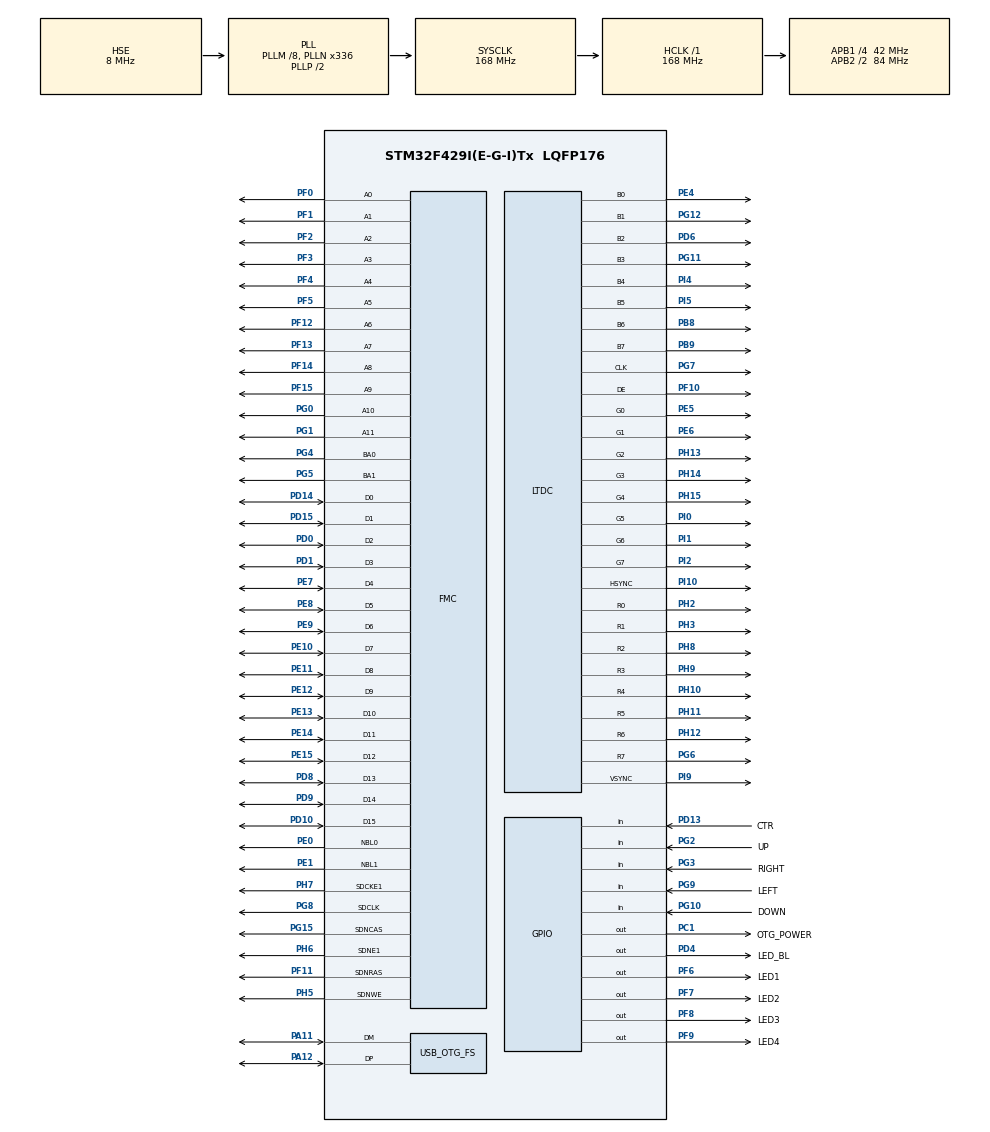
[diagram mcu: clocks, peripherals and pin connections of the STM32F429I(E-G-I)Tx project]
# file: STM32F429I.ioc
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DMA2D.ColorMode=DMA2D_RGB565
DMA2D.InputAlphaForeground=0xFF
DMA2D.InputColorModeForeground=CM_RGB565
DMA2D.Mode=DMA2D_M2M
Dma.MEMTOMEM.0.Channel=DMA_CHANNEL_0
Dma.MEMTOMEM.0.Direction=DMA_MEMORY_TO_MEMORY
Dma.MEMTOMEM.0.FIFOMode=DMA_FIFOMODE_ENABLE
Dma.MEMTOMEM.0.FIFOThreshold=DMA_FIFO_THRESHOLD_FULL
Dma.MEMTOMEM.0.Instance=DMA2_Stream0
Dma.MEMTOMEM.0.MemBurst=DMA_MBURST_SINGLE
Dma.MEMTOMEM.0.MemDataAlignment=DMA_MDATAALIGN_WORD
Dma.MEMTOMEM.0.MemInc=DMA_MINC_ENABLE
Dma.MEMTOMEM.0.Mode=DMA_NORMAL
Dma.MEMTOMEM.0.PeriphBurst=DMA_PBURST_SINGLE
Dma.MEMTOMEM.0.PeriphDataAlignment=DMA_PDATAALIGN_WORD
Dma.MEMTOMEM.0.PeriphInc=DMA_PINC_ENABLE
Dma.MEMTOMEM.0.Priority=DMA_PRIORITY_LOW
Dma.Request0=MEMTOMEM
FMC.CASLatency1=FMC_SDRAM_CAS_LATENCY_3
FMC.ExitSelfRefreshDelay1=7
FMC.LoadToActiveDelay1=2
FMC.RCDDelay1=2
FMC.RPDelay1=2
FMC.RPDelay2=2
FMC.ReadPipeDelay1=FMC_SDRAM_RPIPE_DELAY_1
FMC.ReadPipeDelay2=FMC_SDRAM_RPIPE_DELAY_1
FMC.RowBitsNumber1=FMC_SDRAM_ROW_BITS_NUM_12
FMC.RowCycleDelay1=6
FMC.RowCycleDelay2=6
FMC.SDClockPeriod1=FMC_SDRAM_CLOCK_PERIOD_2
FMC.SDClockPeriod2=FMC_SDRAM_CLOCK_PERIOD_2
FMC.SelfRefreshTime1=4
FMC.WriteRecoveryTime1=2
LTDC.ActiveH=480
LTDC.ActiveW=800
LTDC.Alpha_L0=255
LTDC.BlendingFactor1_L0=LTDC_BLENDING_FACTOR1_CA
LTDC.BlendingFactor1_L1=LTDC_BLENDING_FACTOR1_PAxCA
LTDC.BlendingFactor2_L0=LTDC_BLENDING_FACTOR2_CA
LTDC.BlendingFactor2_L1=LTDC_BLENDING_FACTOR2_PAxCA
LTDC.FBStartAdress_L0=0xD0000000
LTDC.FBStartAdress_L1=0xD0200000
LTDC.HBP=46
LTDC.HFP=210
LTDC.HSync=30
LTDC.ImageHeight_L0=480
LTDC.ImageHeight_L1=480
LTDC.ImageWidth_L0=800
LTDC.ImageWidth_L1=800
LTDC.PixelFormat_L0=LTDC_PIXEL_FORMAT_RGB565
LTDC.PixelFormat_L1=LTDC_PIXEL_FORMAT_RGB565
LTDC.VBP=23
LTDC.VFP=22
LTDC.VSync=10
LTDC.WindowX0_L0=0
LTDC.WindowX0_L1=0
LTDC.WindowX1_L0=800
LTDC.WindowX1_L1=800
LTDC.WindowY0_L0=0
LTDC.WindowY0_L1=0
LTDC.WindowY1_L0=480
LTDC.WindowY1_L1=480
Mcu.Family=STM32F4
Mcu.Name=STM32F429I(E-G-I)Tx
Mcu.Package=LQFP176
NVIC.OTG_FS_IRQn=true\:1\:0\:true
NVIC.PriorityGroup=NVIC_PRIORITYGROUP_4
PA11.Mode=Host_Only
PA11.Signal=USB_OTG_FS_DM
PA12.GPIO_PuPd=GPIO_PULLUP
PA12.Mode=Host_Only
PA12.Signal=USB_OTG_FS_DP
PB8.GPIO_Speed=GPIO_SPEED_HIGH
PB8.Mode=RGB888
PB8.Signal=LTDC_B6
PB9.GPIO_Speed=GPIO_SPEED_HIGH
PB9.Mode=RGB888
PB9.Signal=LTDC_B7
PC1.GPIO_Label=OTG_POWER
PC1.Signal=GPIO_Output
PD0.Signal=FMC_D2_DA2
PD1.Signal=FMC_D3_DA3
PD10.Signal=FMC_D15_DA15
PD13.GPIO_Label=CTR
PD13.GPIO_PuPd=GPIO_PULLUP
PD13.Signal=GPIO_Input
PD14.Signal=FMC_D0_DA0
PD15.Signal=FMC_D1_DA1
PD4.GPIO_Label=LED_BL
PD4.Signal=GPIO_Output
PD6.GPIO_Speed=GPIO_SPEED_HIGH
PD6.Mode=RGB888
PD6.Signal=LTDC_B2
PD8.Signal=FMC_D13_DA13
PD9.Signal=FMC_D14_DA14
PE0.Signal=FMC_NBL0
PE1.Signal=FMC_NBL1
PE10.Signal=FMC_D7_DA7
PE11.Signal=FMC_D8_DA8
PE12.Signal=FMC_D9_DA9
PE13.Signal=FMC_D10_DA10
PE14.Signal=FMC_D11_DA11
PE15.Signal=FMC_D12_DA12
PE4.GPIO_Speed=GPIO_SPEED_HIGH
PE4.Mode=RGB888
PE4.Signal=LTDC_B0
PE5.GPIO_Speed=GPIO_SPEED_HIGH
PE5.Mode=RGB888
PE5.Signal=LTDC_G0
PE6.GPIO_Speed=GPIO_SPEED_HIGH
PE6.Mode=RGB888
PE6.Signal=LTDC_G1
PE7.Signal=FMC_D4_DA4
PE8.Signal=FMC_D5_DA5
PE9.Signal=FMC_D6_DA6
PF0.Signal=FMC_A0
PF1.Signal=FMC_A1
PF10.GPIO_Speed=GPIO_SPEED_HIGH
PF10.Mode=RGB888
PF10.Signal=LTDC_DE
PF11.Signal=FMC_SDNRAS
PF12.Signal=FMC_A6
PF13.Signal=FMC_A7
PF14.Signal=FMC_A8
PF15.Signal=FMC_A9
PF2.Signal=FMC_A2
PF3.Signal=FMC_A3
PF4.Signal=FMC_A4
PF5.Signal=FMC_A5
PF6.GPIO_Label=LED1
PF6.Signal=GPIO_Output
PF7.GPIO_Label=LED2
PF7.Signal=GPIO_Output
PF8.GPIO_Label=LED3
PF8.Signal=GPIO_Output
PF9.GPIO_Label=LED4
PF9.Signal=GPIO_Output
PG0.Signal=FMC_A10
PG1.Signal=FMC_A11
PG10.GPIO_Label=DOWN
PG10.GPIO_PuPd=GPIO_PULLUP
PG10.Signal=GPIO_Input
PG11.GPIO_Speed=GPIO_SPEED_HIGH
PG11.Mode=RGB888
PG11.Signal=LTDC_B3
PG12.GPIO_Speed=GPIO_SPEED_HIGH
PG12.Mode=RGB888
PG12.Signal=LTDC_B1
PG15.Signal=FMC_SDNCAS
PG2.GPIO_Label=UP
PG2.GPIO_PuPd=GPIO_PULLUP
PG2.Signal=GPIO_Input
PG3.GPIO_Label=RIGHT
PG3.GPIO_PuPd=GPIO_PULLUP
PG3.Signal=GPIO_Input
PG4.Signal=FMC_A14_BA0
PG5.Signal=FMC_A15_BA1
PG6.GPIO_Speed=GPIO_SPEED_HIGH
PG6.Mode=RGB888
PG6.Signal=LTDC_R7
PG7.GPIO_Speed=GPIO_SPEED_HIGH
PG7.Mode=RGB888
PG7.Signal=LTDC_CLK
PG8.Signal=FMC_SDCLK
PG9.GPIO_Label=LEFT
PG9.GPIO_PuPd=GPIO_PULLUP
PG9.Signal=GPIO_Input
PH0/OSC_IN.Mode=HSE-External-Oscillator
PH0/OSC_IN.Signal=RCC_OSC_IN
PH1/OSC_OUT.Mode=HSE-External-Oscillator
PH1/OSC_OUT.Signal=RCC_OSC_OUT
PH10.GPIO_Speed=GPIO_SPEED_HIGH
PH10.Mode=RGB888
PH10.Signal=LTDC_R4
PH11.GPIO_Speed=GPIO_SPEED_HIGH
PH11.Mode=RGB888
PH11.Signal=LTDC_R5
PH12.GPIO_Speed=GPIO_SPEED_HIGH
PH12.Mode=RGB888
PH12.Signal=LTDC_R6
PH13.GPIO_Speed=GPIO_SPEED_HIGH
PH13.Mode=RGB888
PH13.Signal=LTDC_G2
PH14.GPIO_Speed=GPIO_SPEED_HIGH
PH14.Mode=RGB888
PH14.Signal=LTDC_G3
PH15.GPIO_Speed=GPIO_SPEED_HIGH
PH15.Mode=RGB888
PH15.Signal=LTDC_G4
PH2.GPIO_Speed=GPIO_SPEED_HIGH
PH2.Mode=RGB888
PH2.Signal=LTDC_R0
PH3.GPIO_Speed=GPIO_SPEED_HIGH
PH3.Mode=RGB888
PH3.Signal=LTDC_R1
PH5.Signal=FMC_SDNWE
PH6.Mode=SdramChipSelect2_1
PH6.Signal=FMC_SDNE1
PH7.Mode=SdramChipSelect2_1
PH7.Signal=FMC_SDCKE1
PH8.GPIO_Speed=GPIO_SPEED_HIGH
PH8.Mode=RGB888
PH8.Signal=LTDC_R2
PH9.GPIO_Speed=GPIO_SPEED_HIGH
PH9.Mode=RGB888
PH9.Signal=LTDC_R3
PI0.GPIO_Speed=GPIO_SPEED_HIGH
PI0.Mode=RGB888
PI0.Signal=LTDC_G5
PI1.GPIO_Speed=GPIO_SPEED_HIGH
PI1.Mode=RGB888
PI1.Signal=LTDC_G6
PI10.GPIO_Speed=GPIO_SPEED_HIGH
PI10.Mode=RGB888
PI10.Signal=LTDC_HSYNC
PI2.GPIO_Speed=GPIO_SPEED_HIGH
PI2.Mode=RGB888
PI2.Signal=LTDC_G7
PI4.GPIO_Speed=GPIO_SPEED_HIGH
PI4.Mode=RGB888
PI4.Signal=LTDC_B4
PI5.GPIO_Speed=GPIO_SPEED_HIGH
PI5.Mode=RGB888
PI5.Signal=LTDC_B5
PI9.GPIO_Speed=GPIO_SPEED_HIGH
PI9.Mode=RGB888
PI9.Signal=LTDC_VSYNC
ProjectManager.TargetToolchain=MDK-ARM V5
RCC.48MHZClocksFreq_Value=48000000
RCC.AHBFreq_Value=168000000
RCC.APB1CLKDivider=RCC_HCLK_DIV4
RCC.APB1Freq_Value=42000000
RCC.APB1TimFreq_Value=84000000
RCC.APB2CLKDivider=RCC_HCLK_DIV2
RCC.APB2Freq_Value=84000000
RCC.APB2TimFreq_Value=168000000
RCC.CortexFreq_Value=168000000
RCC.HCLKFreq_Value=168000000
RCC.HSE_VALUE=8000000
RCC.HSI_VALUE=16000000
RCC.LSE_VALUE=32768
RCC.PLLM=8
RCC.PLLN=336
RCC.PLLQ=7
RCC.PLLSAIN=192
RCC.PLLSAIR=3
RCC.SYSCLKFreq_VALUE=168000000
RCC.SYSCLKSource=RCC_SYSCLKSOURCE_PLLCLK
RCC.VCOOutputFreq_Value=336000000
SH.FMC_A0.0=FMC_A0,12b-sda1
SH.FMC_A1.0=FMC_A1,12b-sda1
SH.FMC_A10.0=FMC_A10,12b-sda1
SH.FMC_A11.0=FMC_A11,12b-sda1
SH.FMC_A14_BA0.0=FMC_BA0,FourSdramBanks1
SH.FMC_A15_BA1.0=FMC_BA1,FourSdramBanks1
SH.FMC_A2.0=FMC_A2,12b-sda1
SH.FMC_A3.0=FMC_A3,12b-sda1
SH.FMC_A4.0=FMC_A4,12b-sda1
SH.FMC_A5.0=FMC_A5,12b-sda1
SH.FMC_A6.0=FMC_A6,12b-sda1
SH.FMC_A7.0=FMC_A7,12b-sda1
SH.FMC_A8.0=FMC_A8,12b-sda1
SH.FMC_A9.0=FMC_A9,12b-sda1
SH.FMC_D0_DA0.0=FMC_D0,sd-16b-d1
SH.FMC_D10_DA10.0=FMC_D10,sd-16b-d1
SH.FMC_D11_DA11.0=FMC_D11,sd-16b-d1
SH.FMC_D12_DA12.0=FMC_D12,sd-16b-d1
SH.FMC_D13_DA13.0=FMC_D13,sd-16b-d1
SH.FMC_D14_DA14.0=FMC_D14,sd-16b-d1
SH.FMC_D15_DA15.0=FMC_D15,sd-16b-d1
SH.FMC_D1_DA1.0=FMC_D1,sd-16b-d1
SH.FMC_D2_DA2.0=FMC_D2,sd-16b-d1
SH.FMC_D3_DA3.0=FMC_D3,sd-16b-d1
SH.FMC_D4_DA4.0=FMC_D4,sd-16b-d1
SH.FMC_D5_DA5.0=FMC_D5,sd-16b-d1
SH.FMC_D6_DA6.0=FMC_D6,sd-16b-d1
SH.FMC_D7_DA7.0=FMC_D7,sd-16b-d1
SH.FMC_D8_DA8.0=FMC_D8,sd-16b-d1
SH.FMC_D9_DA9.0=FMC_D9,sd-16b-d1
SH.FMC_NBL0.0=FMC_NBL0,Sd2ByteEnable1
SH.FMC_NBL1.0=FMC_NBL1,Sd2ByteEnable1
SH.FMC_SDCLK.0=FMC_SDCLK,12b-sda1
SH.FMC_SDNCAS.0=FMC_SDNCAS,12b-sda1
SH.FMC_SDNRAS.0=FMC_SDNRAS,12b-sda1
SH.FMC_SDNWE.0=FMC_SDNWE,12b-sda1
USB_HOST.USBH_DEBUG_LEVEL-HID_FS=2
USB_HOST.USBH_HandleTypeDef-HID_FS=hUsbHostFS
USB_HOST.USBH_MAX_DATA_BUFFER-HID_FS=0x200
USB_HOST.USBH_MAX_SIZE_CONFIGURATION-HID_FS=0x200
USB_HOST.VirtualModeFS=Hid
USB_OTG_FS.phy_itface=HCD_PHY_EMBEDDED
VP_DMA2D_VS_DMA2D.Mode=DMA2D_Activate
VP_USB_HOST_VS_USB_HOST_HID_FS.Mode=HID_FS
board=STM32F429I

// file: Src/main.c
/**
  ******************************************************************************
  * File Name          : main.c
  * Description        : Main program body
  ******************************************************************************
  *
  * COPYRIGHT(c) 2015 STMicroelectronics
  *
  * Redistribution and use in source and binary forms, with or without modification,
  * are permitted provided that the following conditions are met:
  *   1. Redistributions of source code must retain the above copyright notice,
  *      this list of conditions and the following disclaimer.
  *   2. Redistributions in binary form must reproduce the above copyright notice,
  *      this list of conditions and the following disclaimer in the documentation
  *      and/or other materials provided with the distribution.
  *   3. Neither the name of STMicroelectronics nor the names of its contributors
  *      may be used to endorse or promote products derived from this software
  *      without specific prior written permission.
  *
  * THIS SOFTWARE IS PROVIDED BY THE COPYRIGHT HOLDERS AND CONTRIBUTORS "AS IS"
  * AND ANY EXPRESS OR IMPLIED WARRANTIES, INCLUDING, BUT NOT LIMITED TO, THE
  * IMPLIED WARRANTIES OF MERCHANTABILITY AND FITNESS FOR A PARTICULAR PURPOSE ARE
  * DISCLAIMED. IN NO EVENT SHALL THE COPYRIGHT HOLDER OR CONTRIBUTORS BE LIABLE
  * FOR ANY DIRECT, INDIRECT, INCIDENTAL, SPECIAL, EXEMPLARY, OR CONSEQUENTIAL
  * DAMAGES (INCLUDING, BUT NOT LIMITED TO, PROCUREMENT OF SUBSTITUTE GOODS OR
  * SERVICES; LOSS OF USE, DATA, OR PROFITS; OR BUSINESS INTERRUPTION) HOWEVER
  * CAUSED AND ON ANY THEORY OF LIABILITY, WHETHER IN CONTRACT, STRICT LIABILITY,
  * OR TORT (INCLUDING NEGLIGENCE OR OTHERWISE) ARISING IN ANY WAY OUT OF THE USE
  * OF THIS SOFTWARE, EVEN IF ADVISED OF THE POSSIBILITY OF SUCH DAMAGE.
  *
  ******************************************************************************
  */
#include "stm32f4xx_hal.h"
#include "dma.h"
#include "dma2d.h"
#include "ltdc.h"
#include "usb_host.h"
#include "gpio.h"
#include "fmc.h"

/* USER CODE BEGIN Includes */
#include "stm324x9i_sdram.h"
#include "stm324x9i_lcd.h"
#include "main.h"
/* USER CODE END Includes */

/* USER CODE BEGIN PV */
/* Private variables ---------------------------------------------------------*/

/* USER CODE END PV */

void SystemClock_Config(void);
void MX_USB_HOST_Process(void);

/* USER CODE BEGIN PFP */
/* Private function prototypes -----------------------------------------------*/

/* USER CODE END PFP */

int main(void)
{

  /* MCU Configuration----------------------------------------------------------*/

  /* Reset of all peripherals, Initializes the Flash interface and the Systick. */
  HAL_Init();

  /* Configure the system clock */
  SystemClock_Config();

  /* Initialize all configured peripherals */
  MX_GPIO_Init();
  MX_DMA_Init();
  MX_DMA2D_Init();
  MX_FMC_Init();
  MX_LTDC_Init();
  MX_USB_HOST_Init();

  /* USER CODE BEGIN 2 */
	/* Initialize the SDRAM */
  BSP_SDRAM_Init();
	/* Initialize the LCD */
  BSP_LCD_Init();
	/* Clear the LCD Background layer */
  BSP_LCD_SetLayerVisible(1,DISABLE);
  /* Set LCD Foreground Layer  */
  BSP_LCD_SelectLayer(0);

  /* Initialize LCD Log module */
  LCD_LOG_Init();

  /* Show Header and Footer texts */
  LCD_LOG_SetHeader((uint8_t *)" USB OTG FS HID Host");
  LCD_LOG_SetFooter((uint8_t *)"WaveShare Open4X9I-C board");

	LCD_UsrLog("USB Host library started.\n");

	/* Start HID Interface */
  HID_MenuInit();
  /* USER CODE END 2 */

  /* Infinite loop */
  while (1)
  {
    MX_USB_HOST_Process();

  /* USER CODE BEGIN 3 */
		/* HID Menu Process */
    HID_MenuProcess();
  }
  /* USER CODE END 3 */

}

/** System Clock Configuration
*/
void SystemClock_Config(void)
{

  RCC_OscInitTypeDef RCC_OscInitStruct;
  RCC_ClkInitTypeDef RCC_ClkInitStruct;
  RCC_PeriphCLKInitTypeDef PeriphClkInitStruct;

  __PWR_CLK_ENABLE();

  __HAL_PWR_VOLTAGESCALING_CONFIG(PWR_REGULATOR_VOLTAGE_SCALE1);

  RCC_OscInitStruct.OscillatorType = RCC_OSCILLATORTYPE_HSE;
  RCC_OscInitStruct.HSEState = RCC_HSE_ON;
  RCC_OscInitStruct.PLL.PLLState = RCC_PLL_ON;
  RCC_OscInitStruct.PLL.PLLSource = RCC_PLLSOURCE_HSE;
  RCC_OscInitStruct.PLL.PLLM = 8;
  RCC_OscInitStruct.PLL.PLLN = 336;
  RCC_OscInitStruct.PLL.PLLP = RCC_PLLP_DIV2;
  RCC_OscInitStruct.PLL.PLLQ = 7;
  HAL_RCC_OscConfig(&RCC_OscInitStruct);

  RCC_ClkInitStruct.ClockType = RCC_CLOCKTYPE_SYSCLK|RCC_CLOCKTYPE_PCLK1
                              |RCC_CLOCKTYPE_PCLK2;
  RCC_ClkInitStruct.SYSCLKSource = RCC_SYSCLKSOURCE_PLLCLK;
  RCC_ClkInitStruct.AHBCLKDivider = RCC_SYSCLK_DIV1;
  RCC_ClkInitStruct.APB1CLKDivider = RCC_HCLK_DIV4;
  RCC_ClkInitStruct.APB2CLKDivider = RCC_HCLK_DIV2;
  HAL_RCC_ClockConfig(&RCC_ClkInitStruct, FLASH_LATENCY_5);

  PeriphClkInitStruct.PeriphClockSelection = RCC_PERIPHCLK_LTDC;
  PeriphClkInitStruct.PLLSAI.PLLSAIN = 192;
  PeriphClkInitStruct.PLLSAI.PLLSAIR = 3;
  PeriphClkInitStruct.PLLSAIDivR = RCC_PLLSAIDIVR_2;
  HAL_RCCEx_PeriphCLKConfig(&PeriphClkInitStruct);

  HAL_SYSTICK_Config(HAL_RCC_GetHCLKFreq()/1000);

  HAL_SYSTICK_CLKSourceConfig(SYSTICK_CLKSOURCE_HCLK);

  /* SysTick_IRQn interrupt configuration */
  HAL_NVIC_SetPriority(SysTick_IRQn, 0, 0);
}

/************************ (C) COPYRIGHT STMicroelectronics *****END OF FILE****/
